LIN_description_file;
LIN_protocol_version = "2.1";
LIN_language_version = "2.1";
LIN_speed = 19.2 kbps;

Nodes {
  Master: BCM_MASTER_NODE, 1 ms, 0 ms ;
  Slaves: RLS_SLAVE_NODE ;
}

Signals {
  BCM_AutoWipersThreshold: 3, 0, BCM_MASTER_NODE, RLS_SLAVE_NODE ;
  BCM_AmbientLightOn: 1, 0, BCM_MASTER_NODE, RLS_SLAVE_NODE ;
  RLS_FrontWipersMode: 2, 0, RLS_SLAVE_NODE, BCM_MASTER_NODE ;
  SIG_Error: 1, 0, RLS_SLAVE_NODE, BCM_MASTER_NODE ;
  RLS_FrontWipersAutoModeEnabled: 1, 1, RLS_SLAVE_NODE, BCM_MASTER_NODE ;
  RLS_AutoLightOn_0: 2, 0, RLS_SLAVE_NODE, BCM_MASTER_NODE ;
  RLS_AutoLightOn_1: 1, 0, RLS_SLAVE_NODE, BCM_MASTER_NODE ;
  RLS_Unknown_1: 1, 1, RLS_SLAVE_NODE, BCM_MASTER_NODE ;
  RLS_AmbientLightLevel_pow: 2, 0, RLS_SLAVE_NODE, BCM_MASTER_NODE ;
  RLS_TooDarkOutside: 2, 3, RLS_SLAVE_NODE, BCM_MASTER_NODE ;
  RLS_RainDetectedCloseWindows: 1, 0, RLS_SLAVE_NODE, BCM_MASTER_NODE ;
  RLS_AmbientLightLevel: 7, 0, RLS_SLAVE_NODE, BCM_MASTER_NODE ;
  BCM_WipersSwPos: 3, 0, BCM_MASTER_NODE, RLS_SLAVE_NODE ;
  BCM_Washer: 2, 0, BCM_MASTER_NODE, RLS_SLAVE_NODE ;
  BCM_LightSwitchPos: 3, 0, BCM_MASTER_NODE, RLS_SLAVE_NODE ;
  BCM_WipersInOperationNow: 1, 0, BCM_MASTER_NODE, RLS_SLAVE_NODE ;
  BCM_VehicleSpeed: 12, 0, BCM_MASTER_NODE, RLS_SLAVE_NODE ;
  BCM_BatteryVoltage: 8, 0, BCM_MASTER_NODE, RLS_SLAVE_NODE ;
  RLS_LinError: 1, 0, RLS_SLAVE_NODE, BCM_MASTER_NODE ;
  BCM_AllWindowsClosedFlag: 2, 0, BCM_MASTER_NODE, RLS_SLAVE_NODE ;
  BCM_11_Unk_1: 1, 0, BCM_MASTER_NODE, RLS_SLAVE_NODE ;
  BCM_11_CLM_SomeTemp_1DE_2: 8, 0, BCM_MASTER_NODE, RLS_SLAVE_NODE ;
  RLS_8E_Alw_1: 1, 1, RLS_SLAVE_NODE, BCM_MASTER_NODE ;
  RLS_8E_23_CAN_355_56: 9, 31, RLS_SLAVE_NODE, BCM_MASTER_NODE ;
  RLS_Error: 1, 0, RLS_SLAVE_NODE, BCM_MASTER_NODE ;
  BCM_IgnState: 3, 0, BCM_MASTER_NODE, RLS_SLAVE_NODE ;
  BCM_11_Unk_3: 1, 0, BCM_MASTER_NODE, RLS_SLAVE_NODE ;
  BCM_11_Unk_4: 1, 0, BCM_MASTER_NODE, RLS_SLAVE_NODE ;
  BCM_CloseWindowsRequest: 1, 0, BCM_MASTER_NODE, RLS_SLAVE_NODE ;
  BCM_11_Unk_6: 1, 0, BCM_MASTER_NODE, RLS_SLAVE_NODE ;
  BCM_11_Unk_7: 3, 0, BCM_MASTER_NODE, RLS_SLAVE_NODE ;
  BCM_11_Unk_8: 1, 0, BCM_MASTER_NODE, RLS_SLAVE_NODE ;
  BCM_11_CAN_31E_4_and_0x60: 2, 0, BCM_MASTER_NODE, RLS_SLAVE_NODE ;
  BCM_11_if_CAN_4CA_0_and_3_eq_3: 1, 0, BCM_MASTER_NODE, RLS_SLAVE_NODE ;
  BCM_11_CAN_304_0x10: 1, 0, BCM_MASTER_NODE, RLS_SLAVE_NODE ;
  BCM_11_CAN_304_0x20: 1, 0, BCM_MASTER_NODE, RLS_SLAVE_NODE ;
  BCM_11_CAN_304_0x40: 1, 0, BCM_MASTER_NODE, RLS_SLAVE_NODE ;
  BCM_11_CAN_304_0x80: 1, 0, BCM_MASTER_NODE, RLS_SLAVE_NODE ;
  BCM_85_Unk_0: 2, 0, BCM_MASTER_NODE, RLS_SLAVE_NODE ;
  BCM_85_Time_Day: 5, 0, BCM_MASTER_NODE, RLS_SLAVE_NODE ;
  BCM_85_Time_Month: 4, 0, BCM_MASTER_NODE, RLS_SLAVE_NODE ;
  BCM_85_Time_Year: 7, 0, BCM_MASTER_NODE, RLS_SLAVE_NODE ;
  RLS_8E_4_CAN_355_4: 8, 255, RLS_SLAVE_NODE, BCM_MASTER_NODE ;
  RLS_8E_5_CAN_355_3: 8, 255, RLS_SLAVE_NODE, BCM_MASTER_NODE ;
  RLS_8E_6_CAN_355_1: 8, 255, RLS_SLAVE_NODE, BCM_MASTER_NODE ;
  RLS_8E_7_CAN_355_2: 8, 255, RLS_SLAVE_NODE, BCM_MASTER_NODE ;
  IBS_01_3F: 14, 0, BCM_MASTER_NODE, RLS_SLAVE_NODE ;
  IBS_1_C0: 2, 3, BCM_MASTER_NODE, RLS_SLAVE_NODE ;
  IBS_23: 16, 65535, BCM_MASTER_NODE, RLS_SLAVE_NODE ;
  IBS_4: 8, 255, BCM_MASTER_NODE, RLS_SLAVE_NODE ;
  IBS_5: 8, 255, BCM_MASTER_NODE, RLS_SLAVE_NODE ;
  IBS_6_03: 2, 0, BCM_MASTER_NODE, RLS_SLAVE_NODE ;
  IBS_6_0C: 2, 1, BCM_MASTER_NODE, RLS_SLAVE_NODE ;
  IBS_6_30: 2, 0, BCM_MASTER_NODE, RLS_SLAVE_NODE ;
  IBS_6_40: 1, 1, BCM_MASTER_NODE, RLS_SLAVE_NODE ;
  IBS_6_80: 1, 0, BCM_MASTER_NODE, RLS_SLAVE_NODE ;
  IBS_7_01: 1, 1, BCM_MASTER_NODE, RLS_SLAVE_NODE ;
  IBS_7_02: 1, 0, BCM_MASTER_NODE, RLS_SLAVE_NODE ;
}

Frames {
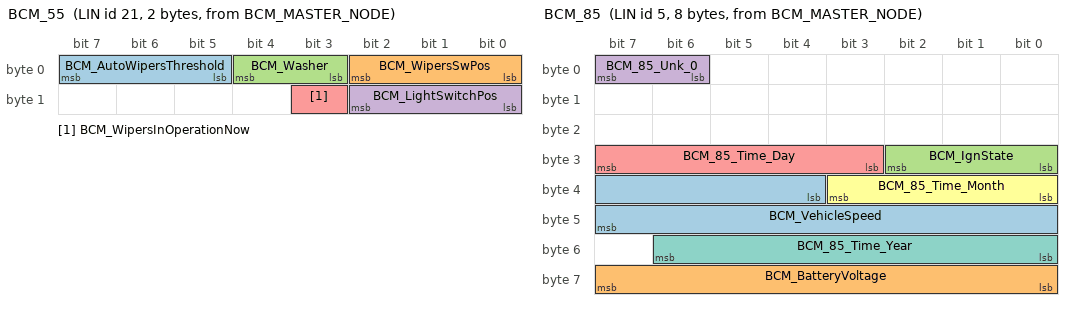
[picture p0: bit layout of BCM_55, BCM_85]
  BCM_55: 21, BCM_MASTER_NODE, 2 {
    BCM_AutoWipersThreshold, 5 ;
    BCM_WipersSwPos, 0 ;
    BCM_Washer, 3 ;
    BCM_LightSwitchPos, 8 ;
    BCM_WipersInOperationNow, 11 ;
  }
  BCM_D6: 22, BCM_MASTER_NODE, 8 {
    BCM_AmbientLightOn, 5 ;
  }
  RLS_8E: 14, RLS_SLAVE_NODE, 8 {
    RLS_FrontWipersMode, 0 ;
    SIG_Error, 3 ;
    RLS_FrontWipersAutoModeEnabled, 2 ;
    RLS_AutoLightOn_0, 5 ;
    RLS_AutoLightOn_1, 4 ;
    RLS_Unknown_1, 7 ;
    RLS_AmbientLightLevel_pow, 12 ;
    RLS_TooDarkOutside, 9 ;
    RLS_RainDetectedCloseWindows, 14 ;
    RLS_AmbientLightLevel, 16 ;
    RLS_LinError, 11 ;
    RLS_8E_Alw_1, 15 ;
    RLS_8E_23_CAN_355_56, 23 ;
    RLS_Error, 8 ;
    RLS_8E_4_CAN_355_4, 32 ;
    RLS_8E_5_CAN_355_3, 40 ;
    RLS_8E_6_CAN_355_1, 48 ;
    RLS_8E_7_CAN_355_2, 56 ;
  }
  BCM_85: 5, BCM_MASTER_NODE, 8 {
    BCM_VehicleSpeed, 36 ;
    BCM_BatteryVoltage, 56 ;
    BCM_IgnState, 24 ;
    BCM_85_Unk_0, 6 ;
    BCM_85_Time_Day, 27 ;
    BCM_85_Time_Month, 32 ;
    BCM_85_Time_Year, 48 ;
  }
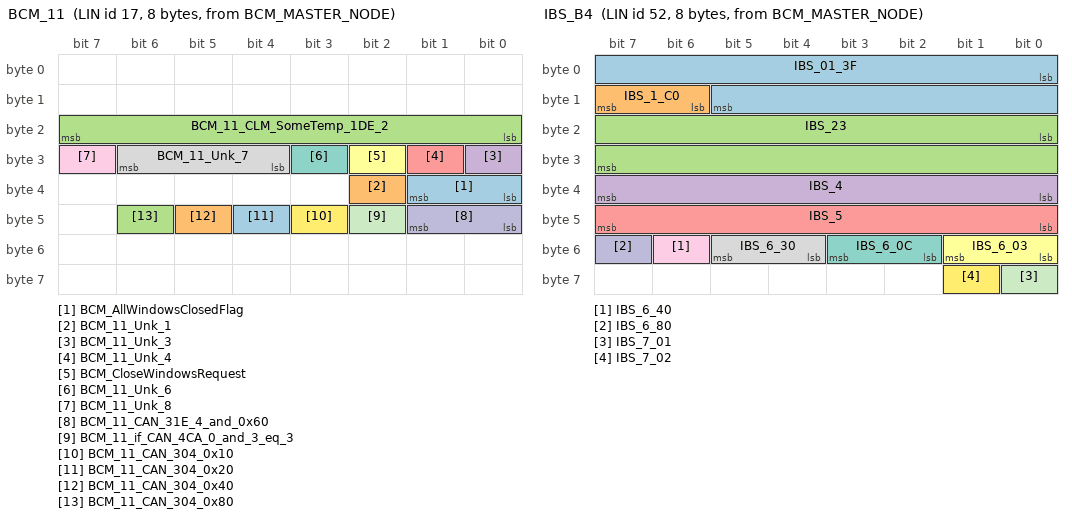
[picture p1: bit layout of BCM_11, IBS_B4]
  BCM_11: 17, BCM_MASTER_NODE, 8 {
    BCM_AllWindowsClosedFlag, 32 ;
    BCM_11_Unk_1, 34 ;
    BCM_11_CLM_SomeTemp_1DE_2, 16 ;
    BCM_11_Unk_3, 24 ;
    BCM_11_Unk_4, 25 ;
    BCM_CloseWindowsRequest, 26 ;
    BCM_11_Unk_6, 27 ;
    BCM_11_Unk_7, 28 ;
    BCM_11_Unk_8, 31 ;
    BCM_11_CAN_31E_4_and_0x60, 40 ;
    BCM_11_if_CAN_4CA_0_and_3_eq_3, 42 ;
    BCM_11_CAN_304_0x10, 43 ;
    BCM_11_CAN_304_0x20, 44 ;
    BCM_11_CAN_304_0x40, 45 ;
    BCM_11_CAN_304_0x80, 46 ;
  }
  IBS_B4: 52, BCM_MASTER_NODE, 8 {
    IBS_01_3F, 0 ;
    IBS_1_C0, 14 ;
    IBS_23, 16 ;
    IBS_4, 32 ;
    IBS_5, 40 ;
    IBS_6_03, 48 ;
    IBS_6_0C, 50 ;
    IBS_6_30, 52 ;
    IBS_6_40, 54 ;
    IBS_6_80, 55 ;
    IBS_7_01, 56 ;
    IBS_7_02, 57 ;
  }
}

Node_attributes {
  RLS_SLAVE_NODE{
    LIN_protocol = "2.1" ;
    configured_NAD = 0x1 ;
    initial_NAD = 0x1 ;
    product_id = 0xFA, 0x1, 0 ;
    response_error = SIG_Error ;
    P2_min = 50 ms ;
    ST_min = 0 ms ;
    N_As_timeout = 1000 ms ;
    N_Cr_timeout = 1000 ms ;
    configurable_frames {
      BCM_55 ;
      RLS_8E ;
      BCM_D6 ;
      BCM_85 ;
      BCM_11 ;
      IBS_B4 ;
    }
  }
}

Schedule_tables {
 ScheduleTable {
    BCM_11 delay 100 ms ;
    BCM_85 delay 100 ms ;
    SlaveResp delay 10 ms ;
    MasterReq delay 10 ms ;
    RLS_8E delay 100 ms ;
    BCM_D6 delay 100 ms ;
    BCM_55 delay 50 ms ;
    IBS_B4 delay 10 ms ;
  }
}

Signal_encoding_types {
  BCM_85_IgnState_Encoding {
    logical_value, 0, "IGN_OFF" ;
    logical_value, 1, "IGN_ACC" ;
    logical_value, 2, "IGN_ON" ;
    logical_value, 3, "IGN_ENGINE_START_PROCESS" ;
  }
  BCM_AllWindowsClosedFlag_Encoding {
    logical_value, 0, "Any window is opened" ;
    logical_value, 1, "All windows are closed" ;
  }
  BCM_BatteryVoltage_Encoding {
    physical_value, 0, 0, 0.1, 0, "V" ;
  }
  RLS_FrontWipersMode_Encoding {
    logical_value, 0, "WIPERS_OFF" ;
    logical_value, 1, "WIPERS_1_TIME" ;
    logical_value, 2, "WIPERS_SLOW" ;
    logical_value, 3, "WIPERS_FAST" ;
  }
}

Signal_representation {
  BCM_85_IgnState_Encoding: BCM_IgnState ;
  BCM_AllWindowsClosedFlag_Encoding: BCM_AllWindowsClosedFlag ;
  BCM_BatteryVoltage_Encoding: BCM_BatteryVoltage ;
  RLS_FrontWipersMode_Encoding: RLS_FrontWipersMode ;
}
